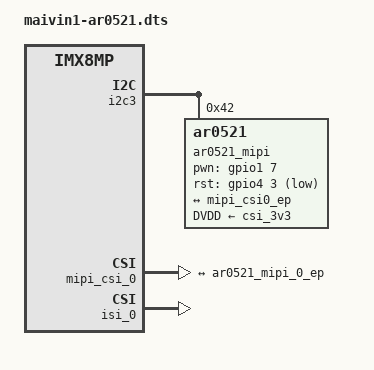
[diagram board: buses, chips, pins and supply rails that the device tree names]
// SPDX-License-Identifier: AGPL-3.0
/*
 * Copyright 2023 Au-Zone Technologies
 */

// Maivin 1 Camera Overlay for the AR0521 Sensor

/dts-v1/;
/plugin/;

#include <dt-bindings/clock/imx8mp-clock.h>
#include <dt-bindings/gpio/gpio.h>

#include "imx8mp-pinfunc.h"

/ {
	compatible = "toradex,verdin-imx8mp";
};

/* Verdin I2C_4_CSI */
&i2c3 {
	#address-cells = <1>;
	#size-cells = <0>;
	status = "okay";

	ar0521_mipi@42 {
		compatible = "ar0521";
		reg = <0x42>;
		pinctrl-names = "default";
		pinctrl-0 = <&pinctrl_csi1_control>;
		DVDD-supply = <&csi_3v3>;
		assigned-clocks = <&clk IMX8MP_CLK_IPP_DO_CLKO2>;
		assigned-clock-parents = <&clk IMX8MP_CLK_24M>;
		assigned-clock-rates = <24000000>;
		clocks = <&clk_dummy>;
		clock-names = "csi_mclk";
		mclk = <24000000>;
		mclk_source = <0>;
		mipi_csi;
		camera_mipi_lanes = <4>;
		csi_id = <0>;
		status = "okay";

		pwn-gpios = <&gpio1 7 GPIO_ACTIVE_HIGH>;
		rst-gpios = <&gpio4 3 GPIO_ACTIVE_LOW>;

		port {
			ar0521_mipi_0_ep: endpoint {
				data-lanes = <1 2 3 4>;
				clock-lanes = <0>;
				max-pixel-frequency = /bits/ 64 <500000000>;
				remote-endpoint = <&mipi_csi0_ep>;
			};
		};
	};
};

&mipi_csi_0 {
	#address-cells = <1>;
	#size-cells = <0>;
	status = "okay";

	port@0 {
		reg = <0>;
		mipi_csi0_ep: endpoint {
			remote-endpoint = <&ar0521_mipi_0_ep>;
			data-lanes = <4>;
			csis-hs-settle = <16>;
			csis-clk-settle = <2>;
			csis-wclk;
		};
	};
};

/*
 * AR0521 goes through the plain ISI capture path, not the ISP (unlike
 * OS08A20 -- see maivin1-os08a20.dts). This used to live in the shared
 * maivin1.dts base overlay, which meant loading maivin1-os08a20.dtbo instead
 * of maivin1-ar0521.dtbo still enabled isi_0.cap_device for no reason -- it
 * doesn't touch the OS08A20 ISP path either way (isp_0's actual sensor
 * binding is done by isp_media_server via maivin-isp-detect, not this DT
 * node), but it's dead weight the OS08A20 config shouldn't carry. Moved here
 * so each camera overlay only enables what it actually needs, matching
 * maivin2-os08a20.dts's pattern of never touching isi_0 at all.
 */
&isi_0 {
	status = "okay";

	cap_device {
		status = "okay";
	};
};
